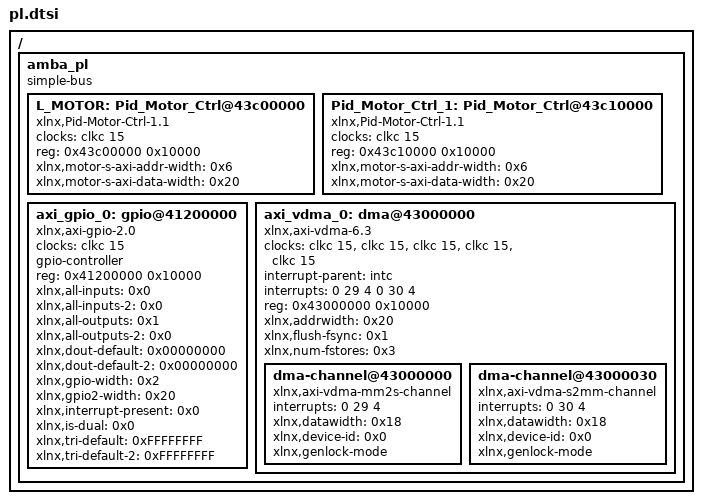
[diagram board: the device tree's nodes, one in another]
/*
 * CAUTION: This file is automatically generated by Xilinx.
 * Version:  
 * Today is: Wed Jan 23 16:51:31 2019
 */


/ {
	amba_pl: amba_pl {
		#address-cells = <1>;
		#size-cells = <1>;
		compatible = "simple-bus";
		ranges ;
		L_MOTOR: Pid_Motor_Ctrl@43c00000 {
			clock-names = "motor_s_axi_aclk";
			clocks = <&clkc 15>;
			compatible = "xlnx,Pid-Motor-Ctrl-1.1";
			reg = <0x43c00000 0x10000>;
			xlnx,motor-s-axi-addr-width = <0x6>;
			xlnx,motor-s-axi-data-width = <0x20>;
		};
		Pid_Motor_Ctrl_1: Pid_Motor_Ctrl@43c10000 {
			clock-names = "motor_s_axi_aclk";
			clocks = <&clkc 15>;
			compatible = "xlnx,Pid-Motor-Ctrl-1.1";
			reg = <0x43c10000 0x10000>;
			xlnx,motor-s-axi-addr-width = <0x6>;
			xlnx,motor-s-axi-data-width = <0x20>;
		};
		axi_gpio_0: gpio@41200000 {
			#gpio-cells = <3>;
			clock-names = "s_axi_aclk";
			clocks = <&clkc 15>;
			compatible = "xlnx,axi-gpio-2.0", "xlnx,xps-gpio-1.00.a";
			gpio-controller ;
			reg = <0x41200000 0x10000>;
			xlnx,all-inputs = <0x0>;
			xlnx,all-inputs-2 = <0x0>;
			xlnx,all-outputs = <0x1>;
			xlnx,all-outputs-2 = <0x0>;
			xlnx,dout-default = <0x00000000>;
			xlnx,dout-default-2 = <0x00000000>;
			xlnx,gpio-width = <0x2>;
			xlnx,gpio2-width = <0x20>;
			xlnx,interrupt-present = <0x0>;
			xlnx,is-dual = <0x0>;
			xlnx,tri-default = <0xFFFFFFFF>;
			xlnx,tri-default-2 = <0xFFFFFFFF>;
		};
		axi_vdma_0: dma@43000000 {
			#dma-cells = <1>;
			clock-names = "s_axi_lite_aclk", "m_axi_mm2s_aclk", "m_axis_mm2s_aclk", "m_axi_s2mm_aclk", "s_axis_s2mm_aclk";
			clocks = <&clkc 15>, <&clkc 15>, <&clkc 15>, <&clkc 15>, <&clkc 15>;
			compatible = "xlnx,axi-vdma-6.3", "xlnx,axi-vdma-1.00.a";
			interrupt-names = "mm2s_introut", "s2mm_introut";
			interrupt-parent = <&intc>;
			interrupts = <0 29 4 0 30 4>;
			reg = <0x43000000 0x10000>;
			xlnx,addrwidth = <0x20>;
			xlnx,flush-fsync = <0x1>;
			xlnx,num-fstores = <0x3>;
			dma-channel@43000000 {
				compatible = "xlnx,axi-vdma-mm2s-channel";
				interrupts = <0 29 4>;
				xlnx,datawidth = <0x18>;
				xlnx,device-id = <0x0>;
				xlnx,genlock-mode ;
			};
			dma-channel@43000030 {
				compatible = "xlnx,axi-vdma-s2mm-channel";
				interrupts = <0 30 4>;
				xlnx,datawidth = <0x18>;
				xlnx,device-id = <0x0>;
				xlnx,genlock-mode ;
			};
		};
	};
};
